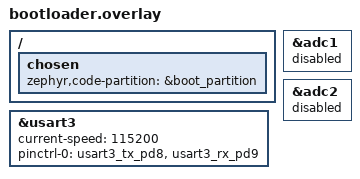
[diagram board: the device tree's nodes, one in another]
/ {
    chosen {
        zephyr,code-partition = &boot_partition;
    };
};

&usart3 {
    current-speed = <115200>;
    pinctrl-0 = <&usart3_tx_pd8 &usart3_rx_pd9>;
    pinctrl-names = "default";
};

&adc1 {
    status = "disabled";
};

&adc2 {
    status = "disabled";
};
